# SRAM2MB register map
Registers from a debugger description file.
Registers are 32-bit, access not given, no defined reset value unless marked. A register's access mark holds for its fields unless they carry their own. Addresses are absolute; registers are grouped by the start of their names; lines under a group give offsets from that group; [hi:lo] are bit positions; {n}, {i} and the like mark numbered series; 'fields as' and 'values as' point back to an identical list; <NAME> marks a mode.

## SFR
0x400F3000 RAMPCMD
  [0] PROTREL
0x400F3100 RAMEDC
  [0] ECC_ENABLE
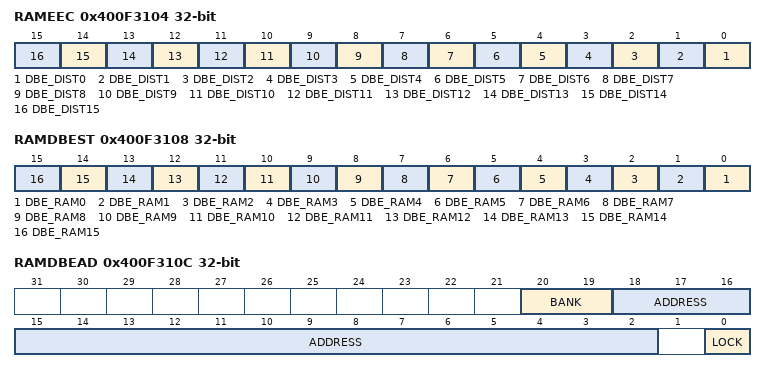
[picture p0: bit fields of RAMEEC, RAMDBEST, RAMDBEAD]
0x400F3104 RAMEEC
  [n] DBE_DIST{n} (n=0..15)
0x400F3108 RAMDBEST ro
  [n] DBE_RAM{n} (n=0..15)
0x400F310C RAMDBEAD ro
  [20:19] BANK, [18:2] ADDRESS, [0] LOCK
0x400F3110 RAMDBECNT ro
  [3:0] ERRCOUNT
